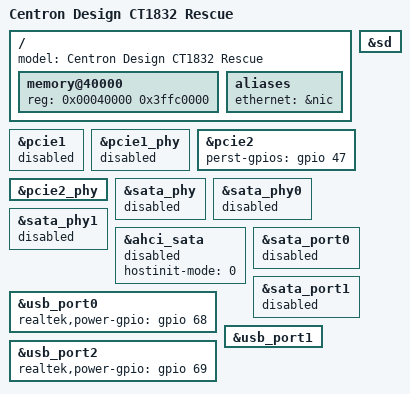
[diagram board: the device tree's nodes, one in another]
// SPDX-License-Identifier: GPL-2.0
/*
 * Copyright (c) 2019-2021 Realtek Semiconductor Corp.
 */

/dts-v1/;

#include "rtd16xxb-rescue.dtsi"

/ {
	model = "Centron Design CT1832 Rescue";

	memory@40000 {
		device_type = "memory";
		reg = <0x00040000 0x3ffc0000>; /* 1 GiB */
	};

	aliases {
		ethernet = &nic;
	};
};

&sd {
	status = "okay";
};

&pcie1 {
	/delete-property/perst-gpios;
	status = "disabled";
};

&pcie1_phy {
	status = "disabled";
};

&pcie2 {
	status = "okay";
	perst-gpios = <&gpio 47 GPIO_ACTIVE_HIGH>;
};

&pcie2_phy {
	status = "okay";
};

&sata_phy {
	status = "disabled";
};

&sata_phy0 {
	status = "disabled";
};

&sata_phy1 {
	status = "disabled";
};

&ahci_sata {
	hostinit-mode = <0>;
	status = "disabled";
};

&sata_port0 {
	status = "disabled";
};

&sata_port1 {
	status = "disabled";
};

&usb_port0 {
	realtek,power-gpio = <&gpio 68 GPIO_ACTIVE_HIGH>;
};

&usb_port1 {
	/delete-property/realtek,power-gpio;
};

&usb_port2 {
	realtek,power-gpio = <&gpio 69 GPIO_ACTIVE_HIGH>;
};
